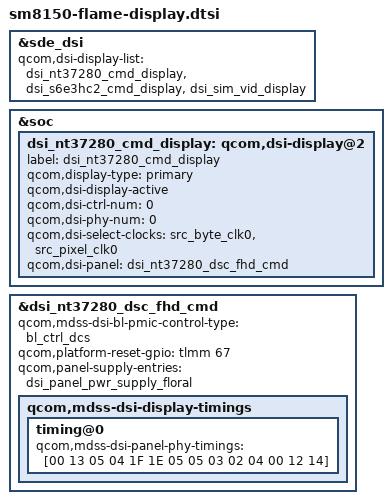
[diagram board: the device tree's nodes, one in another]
/* Copyright (c) 2018, The Linux Foundation. All rights reserved.
 *
 * This program is free software; you can redistribute it and/or modify
 * it under the terms of the GNU General Public License version 2 and
 * only version 2 as published by the Free Software Foundation.
 *
 * This program is distributed in the hope that it will be useful,
 * but WITHOUT ANY WARRANTY; without even the implied warranty of
 * MERCHANTABILITY or FITNESS FOR A PARTICULAR PURPOSE.  See the
 * GNU General Public License for more details.
 */

#include "dsi-panel-nt37280-dsc-fhd-cmd.dtsi"

&sde_dsi {
	qcom,dsi-display-list = <&dsi_nt37280_cmd_display
				 &dsi_s6e3hc2_cmd_display
				 &dsi_sim_vid_display>;
};

&soc {
	dsi_nt37280_cmd_display: qcom,dsi-display@2 {
		label = "dsi_nt37280_cmd_display";
		qcom,display-type = "primary";
		qcom,dsi-display-active;

		qcom,dsi-ctrl-num = <0>;
		qcom,dsi-phy-num = <0>;
		qcom,dsi-select-clocks = "src_byte_clk0", "src_pixel_clk0";

		qcom,dsi-panel = <&dsi_nt37280_dsc_fhd_cmd>;
	};
};

&dsi_nt37280_dsc_fhd_cmd {
	qcom,mdss-dsi-bl-pmic-control-type = "bl_ctrl_dcs";
	qcom,platform-reset-gpio = <&tlmm 67 0>;

	qcom,panel-supply-entries = <&dsi_panel_pwr_supply_floral>;

	qcom,mdss-dsi-display-timings {
		timing@0 {
			qcom,mdss-dsi-panel-phy-timings =
				[00 13 05 04 1F 1E 05 05 03 02 04 00 12 14];
		};
	};
};
